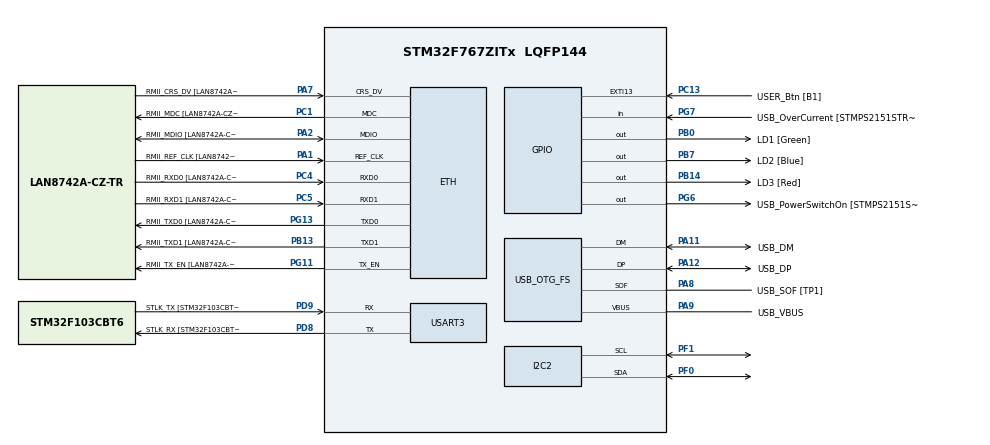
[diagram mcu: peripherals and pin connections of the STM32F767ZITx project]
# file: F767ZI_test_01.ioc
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ETH.MediaInterface=HAL_ETH_RMII_MODE
ETH.PHY_Name=LAN8742A_PHY_ADDRESS
ETH.PHY_Value=0
ETH.PhyAddress=0
FREERTOS.Tasks01=defaultTask,0,128,StartDefaultTask,Default,NULL,Dynamic,NULL,NULL
I2C2.Timing=0x20404768
LWIP.BSP.number=1
LWIP.DHCP_DEBUG=LWIP_DBG_ON
LWIP.LWIP_DNS=1
LWIP.LWIP_ICMP=1
LWIP.Version=v2.1.2_Cube
LWIP0.BSP.STBoard=false
LWIP0.BSP.api=BSP_COMPONENT_DRIVER
LWIP0.BSP.component=LAN8742
LWIP0.BSP.instance=LAN8742
LWIP0.BSP.name=Driver_PHY
LWIP0.BSP.semaphore=S_LAN8742
LWIP0.BSP.solution=LAN8742
Mcu.Family=STM32F7
Mcu.Name=STM32F767ZITx
Mcu.Package=LQFP144
NVIC.ETH_IRQn=true\:5\:0\:false\:false\:true\:true\:false\:true\:true
NVIC.ETH_WKUP_IRQn=true\:5\:0\:false\:false\:true\:true\:true\:true\:true
NVIC.PriorityGroup=NVIC_PRIORITYGROUP_4
NVIC.TIM5_IRQn=true\:15\:0\:false\:false\:true\:false\:false\:true\:true
NVIC.TimeBase=TIM5_IRQn
NVIC.TimeBaseIP=TIM5
PA1.GPIO_Label=RMII_REF_CLK [LAN8742A-CZ-TR_REFCLK0]
PA1.Mode=RMII
PA1.Signal=ETH_REF_CLK
PA10.GPIO_Label=USB_ID
PA10.Signal=USB_OTG_FS_ID
PA11.GPIO_Label=USB_DM
PA11.Mode=Device_Only
PA11.Signal=USB_OTG_FS_DM
PA12.GPIO_Label=USB_DP
PA12.Mode=Device_Only
PA12.Signal=USB_OTG_FS_DP
PA13.GPIO_Label=TMS
PA13.Mode=Serial_Wire
PA13.Signal=SYS_JTMS-SWDIO
PA14.GPIO_Label=TCK
PA14.Mode=Serial_Wire
PA14.Signal=SYS_JTCK-SWCLK
PA2.GPIO_Label=RMII_MDIO [LAN8742A-CZ-TR_MDIO]
PA2.Mode=RMII
PA2.Signal=ETH_MDIO
PA7.GPIO_Label=RMII_CRS_DV [LAN8742A-CZ-TR_CRS_DV]
PA7.Mode=RMII
PA7.Signal=ETH_CRS_DV
PA8.GPIO_Label=USB_SOF [TP1]
PA8.Mode=Activate_SOF_FS
PA8.Signal=USB_OTG_FS_SOF
PA9.GPIO_Label=USB_VBUS
PA9.Mode=Activate_VBUS
PA9.Signal=USB_OTG_FS_VBUS
PB0.GPIO_Label=LD1 [Green]
PB0.Signal=GPIO_Output
PB13.GPIO_Label=RMII_TXD1 [LAN8742A-CZ-TR_TXD1]
PB13.Mode=RMII
PB13.Signal=ETH_TXD1
PB14.GPIO_Label=LD3 [Red]
PB14.Signal=GPIO_Output
PB3.GPIO_Label=SWO
PB3.Signal=SYS_JTDO-SWO
PB7.GPIO_Label=LD2 [Blue]
PB7.Signal=GPIO_Output
PC1.GPIO_Label=RMII_MDC [LAN8742A-CZ-TR_MDC]
PC1.Mode=RMII
PC1.Signal=ETH_MDC
PC13.GPIO_Label=USER_Btn [B1]
PC13.Signal=GPXTI13
PC14/OSC32_IN.Mode=LSE-External-Oscillator
PC14/OSC32_IN.Signal=RCC_OSC32_IN
PC15/OSC32_OUT.Mode=LSE-External-Oscillator
PC15/OSC32_OUT.Signal=RCC_OSC32_OUT
PC4.GPIO_Label=RMII_RXD0 [LAN8742A-CZ-TR_RXD0]
PC4.Mode=RMII
PC4.Signal=ETH_RXD0
PC5.GPIO_Label=RMII_RXD1 [LAN8742A-CZ-TR_RXD1]
PC5.Mode=RMII
PC5.Signal=ETH_RXD1
PD8.GPIO_Label=STLK_RX [STM32F103CBT6_PA3]
PD8.Mode=Asynchronous
PD8.Signal=USART3_TX
PD9.GPIO_Label=STLK_TX [STM32F103CBT6_PA2]
PD9.Mode=Asynchronous
PD9.Signal=USART3_RX
PF0.Mode=I2C
PF0.Signal=I2C2_SDA
PF1.Mode=I2C
PF1.Signal=I2C2_SCL
PG11.GPIO_Label=RMII_TX_EN [LAN8742A-CZ-TR_TXEN]
PG11.Mode=RMII
PG11.Signal=ETH_TX_EN
PG13.GPIO_Label=RMII_TXD0 [LAN8742A-CZ-TR_TXD0]
PG13.Mode=RMII
PG13.Signal=ETH_TXD0
PG6.GPIO_Label=USB_PowerSwitchOn [STMPS2151STR_EN]
PG6.Signal=GPIO_Output
PG7.GPIO_Label=USB_OverCurrent [STMPS2151STR_FAULT]
PG7.Signal=GPIO_Input
PH0/OSC_IN.GPIO_Label=MCO [STM32F103CBT6_PA8]
PH0/OSC_IN.Mode=HSE-External-Clock-Source
PH0/OSC_IN.Signal=RCC_OSC_IN
PH1/OSC_OUT.Mode=HSE-External-Clock-Source
PH1/OSC_OUT.Signal=RCC_OSC_OUT
ProjectManager.HeapSize=0x800
ProjectManager.StackSize=0x1000
ProjectManager.TargetToolchain=Makefile
RCC.48MHZClocksFreq_Value=24000000
RCC.AHBFreq_Value=216000000
RCC.APB1CLKDivider=RCC_HCLK_DIV4
RCC.APB1Freq_Value=54000000
RCC.APB1TimFreq_Value=108000000
RCC.APB2CLKDivider=RCC_HCLK_DIV2
RCC.APB2Freq_Value=108000000
RCC.APB2TimFreq_Value=216000000
RCC.CortexFreq_Value=216000000
RCC.HCLKFreq_Value=216000000
RCC.HSE_VALUE=8000000
RCC.HSI_VALUE=16000000
RCC.PLLM=4
RCC.PLLMUL=RCC_PLL_MUL9
RCC.PLLN=216
RCC.PLLQ=9
RCC.PRESCALERUSB=RCC_USBCLKSOURCE_PLL_DIV1_5
RCC.SYSCLKFreq_VALUE=216000000
RCC.SYSCLKSource=RCC_SYSCLKSOURCE_PLLCLK
RCC.SYSCLKSourceVirtual=RCC_SYSCLKSOURCE_PLLCLK
RCC.USBFreq_Value=48000000
RCC.VCOOutputFreq_Value=432000000
USART3.VirtualMode-Asynchronous=VM_ASYNC
USB_OTG_FS.VirtualMode=Device_Only
VP_FREERTOS_VS_CMSIS_V1.Mode=CMSIS_V1
VP_LWIP_VS_Enabled.Mode=Enabled
VP_SYS_VS_tim5.Mode=TIM5
board=NUCLEO-F767ZI

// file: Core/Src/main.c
/* USER CODE BEGIN Header */
/**
  ******************************************************************************
  * @file           : main.c
  * @brief          : Main program body
  ******************************************************************************
  * @attention
  *
  * Copyright (c) 2023 STMicroelectronics.
  * All rights reserved.
  *
  * This software is licensed under terms that can be found in the LICENSE file
  * in the root directory of this software component.
  * If no LICENSE file comes with this software, it is provided AS-IS.
  *
  ******************************************************************************
  */
/* USER CODE END Header */
#include "main.h"
#include "cmsis_os.h"
#include "i2c.h"
#include "lwip.h"
#include "usart.h"
#include "usb_otg.h"
#include "gpio.h"

void SystemClock_Config(void);
void MX_FREERTOS_Init(void);

int main(void)
{

  /* MCU Configuration--------------------------------------------------------*/

  /* Reset of all peripherals, Initializes the Flash interface and the Systick. */
  HAL_Init();

  /* Configure the system clock */
  SystemClock_Config();

  /* Initialize all configured peripherals */
  MX_GPIO_Init();
  MX_USART3_UART_Init();
  MX_USB_OTG_FS_PCD_Init();
  MX_I2C2_Init();

  /* Call init function for freertos objects (in freertos.c) */
  MX_FREERTOS_Init();

  /* Start scheduler */
  osKernelStart();

  /* We should never get here as control is now taken by the scheduler */
  /* Infinite loop */
  while (1)
  {

  }
}

void SystemClock_Config(void)
{
  LL_FLASH_SetLatency(LL_FLASH_LATENCY_7);
  while(LL_FLASH_GetLatency()!= LL_FLASH_LATENCY_7)
  {
  }
  LL_PWR_SetRegulVoltageScaling(LL_PWR_REGU_VOLTAGE_SCALE1);
  LL_PWR_EnableOverDriveMode();
  LL_RCC_HSE_EnableBypass();
  LL_RCC_HSE_Enable();

   /* Wait till HSE is ready */
  while(LL_RCC_HSE_IsReady() != 1)
  {

  }
  LL_RCC_PLL_ConfigDomain_SYS(LL_RCC_PLLSOURCE_HSE, LL_RCC_PLLM_DIV_4, 216, LL_RCC_PLLP_DIV_2);
  LL_RCC_PLL_ConfigDomain_48M(LL_RCC_PLLSOURCE_HSE, LL_RCC_PLLM_DIV_4, 216, LL_RCC_PLLQ_DIV_9);
  LL_RCC_PLL_Enable();

   /* Wait till PLL is ready */
  while(LL_RCC_PLL_IsReady() != 1)
  {

  }
  while (LL_PWR_IsActiveFlag_VOS() == 0)
  {
  }
  LL_RCC_SetAHBPrescaler(LL_RCC_SYSCLK_DIV_1);
  LL_RCC_SetAPB1Prescaler(LL_RCC_APB1_DIV_4);
  LL_RCC_SetAPB2Prescaler(LL_RCC_APB2_DIV_2);
  LL_RCC_SetSysClkSource(LL_RCC_SYS_CLKSOURCE_PLL);

   /* Wait till System clock is ready */
  while(LL_RCC_GetSysClkSource() != LL_RCC_SYS_CLKSOURCE_STATUS_PLL)
  {

  }
  LL_SetSystemCoreClock(216000000);

   /* Update the time base */
  if (HAL_InitTick (TICK_INT_PRIORITY) != HAL_OK)
  {
    Error_Handler();
  }
}

void HAL_TIM_PeriodElapsedCallback(TIM_HandleTypeDef *htim)
{
  if (htim->Instance == TIM5) {
    HAL_IncTick();
  }
}

void Error_Handler(void)
{
  __disable_irq();
  while (1)
  {
  }
}

#ifdef  USE_FULL_ASSERT
/**
  * @brief  Reports the name of the source file and the source line number
  *         where the assert_param error has occurred.
  * @param  file: pointer to the source file name
  * @param  line: assert_param error line source number
  * @retval None
  */
void assert_failed(uint8_t *file, uint32_t line)
{
  /* USER CODE BEGIN 6 */
  /* User can add his own implementation to report the file name and line number,
     ex: printf("Wrong parameters value: file %s on line %d\r\n", file, line) */
  printf("Wrong parameters value: file %s on line %lu\r\n", file, line);
  /* USER CODE END 6 */
}
#endif /* USE_FULL_ASSERT */

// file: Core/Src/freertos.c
/* USER CODE BEGIN Header */
/**
  ******************************************************************************
  * File Name          : freertos.c
  * Description        : Code for freertos applications
  ******************************************************************************
  * @attention
  *
  * Copyright (c) 2023 STMicroelectronics.
  * All rights reserved.
  *
  * This software is licensed under terms that can be found in the LICENSE file
  * in the root directory of this software component.
  * If no LICENSE file comes with this software, it is provided AS-IS.
  *
  ******************************************************************************
  */
/* USER CODE END Header */

#include "FreeRTOS.h"
#include "task.h"
#include "main.h"
#include "cmsis_os.h"

osThreadId defaultTaskHandle;

void StartDefaultTask(void const * argument);

extern void MX_LWIP_Init(void);
void MX_FREERTOS_Init(void); /* (MISRA C 2004 rule 8.1) */

/* GetIdleTaskMemory prototype (linked to static allocation support) */
void vApplicationGetIdleTaskMemory( StaticTask_t **ppxIdleTaskTCBBuffer, StackType_t **ppxIdleTaskStackBuffer, uint32_t *pulIdleTaskStackSize );

/* USER CODE BEGIN GET_IDLE_TASK_MEMORY */
static StaticTask_t xIdleTaskTCBBuffer;
static StackType_t xIdleStack[configMINIMAL_STACK_SIZE];

void vApplicationGetIdleTaskMemory( StaticTask_t **ppxIdleTaskTCBBuffer, StackType_t **ppxIdleTaskStackBuffer, uint32_t *pulIdleTaskStackSize )
{
  *ppxIdleTaskTCBBuffer = &xIdleTaskTCBBuffer;
  *ppxIdleTaskStackBuffer = &xIdleStack[0];
  *pulIdleTaskStackSize = configMINIMAL_STACK_SIZE;
  /* place for user code */
}
/* USER CODE END GET_IDLE_TASK_MEMORY */

void MX_FREERTOS_Init(void) {

  /* Create the thread(s) */
  /* definition and creation of defaultTask */
  osThreadDef(defaultTask, StartDefaultTask, osPriorityNormal, 0, 128*8);
  defaultTaskHandle = osThreadCreate(osThread(defaultTask), NULL);

}

void StartDefaultTask(void const * argument)
{
  /* init code for LWIP */
  MX_LWIP_Init();
  for(;;)
  {
    osDelay(1);
  }
}
